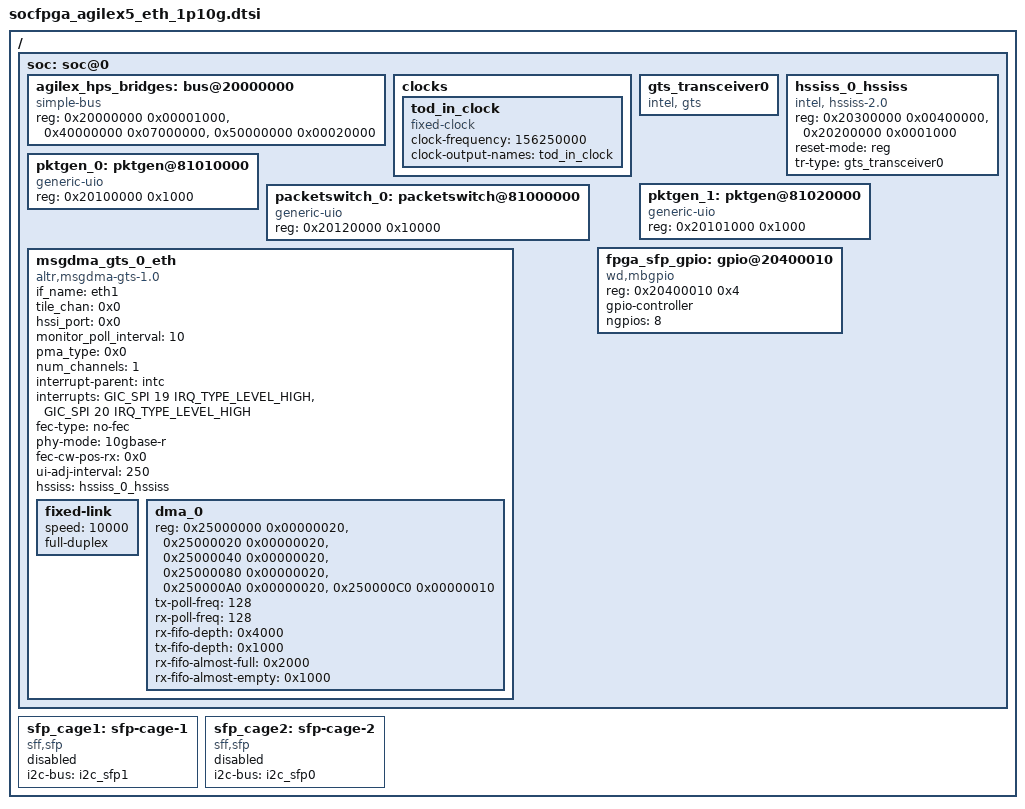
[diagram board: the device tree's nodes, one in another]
// SPDX-License-Identifier: GPL-2.0
/*
 * Copyright(C) 2024 Intel Corporation
 */

//original:
//user_csr 0x0020_0000  0x4020_0000  0x0000_1000
//qhip     0x0030_0000  0x4030_0000  0x0010_0000
//qsfpctrl 0x0404_0000  0x4404_0000  0x0000_4000
//msgdma   0x0500_0000  0x4500_0000  0x0000_0400
//pktcli   0x1000_0000  0x5000_0000  0x0000_1000
//pktsw    0x1001_0000  0x5001_0000  0x0001_0000

//new:
//          Offset       Absolute     Size
// user_csr 0x0020_0000  0x2020_0000  0x0000_1000
// qhip     0x0030_0000  0x2030_0000  0x0010_0000
// qsfpctrl Removed 
// msgdma   0x0500_0000  0x2500_0000  0x0000_0400
// pktcli   0x0010_0000  0x2010_0000  0x0000_1000
// pktsw    0x0012_0000  0x2012_0000  0x0001_0000


// FPGA DDR (2 Gbyte, still working on the other 2 Gbyte ...)
// 0x04_8000_0000 to 0x04_FFFF_FFFF

//The first 32-bit word in each ranges entry represents the child bus flags (or Chip Select / ID), which differentiates between the different physical AXI bridges or address spaces on the Agilex SoC.
//## Breakdown of the Values
//The node specifies #address-cells = <2>;, meaning a child address is made of two 32-bit words.
//
//* 0x00000000 points to the Lightweight HPS-to-FPGA (h2f_lw) bridge.
//* 0x00000001 points to the Main HPS-to-FPGA (h2f) data bridge.
//
//## How the ranges Format Works
//Each mapping inside ranges follows this structure based on your cell counts:
//[child-address-high] [child-address-low] [parent-address] [size]
//Here is how the first two entries map out:
//
//* Lightweight Bridge Mapping:
//
//<0x00000000 0x00000000 0x20000000 0x00001000>
// │          │          │          └─ Size (4KB)
// │          │          └─ Parent Base (0x20000000 in CPU space)
// └─┬────────┘
//   └─ Child Base Address (ID 0, offset 0x0)
//
//* Ethernet Subsystem Mapping:
//
//<0x00000001 0x40000000 0x40000000 0x04000000>
// │          │          │          └─ Size (64MB)
// │          │          └─ Parent Base (0x40000000 in CPU space)
// └─┬────────┘
//   └─ Child Base Address (ID 1, offset 0x40000000)
//
//
//## Why is it structured this way?
//Altera/Intel Agilex SoCs use these ID bits to let the Linux kernel drivers know which physical interconnect/bridge
//path a peripheral belongs to, allowing the system to accurately translate a peripheral's local register space back
//to the main CPU physical memory map.


/{
	soc: soc@0{
//		agilex_hps_bridges: bus@20000000 {
//                compatible = "simple-bus";
//                reg = <0x20000000 0x00001000>,
//                      <0x40000000 0x07000000>,
//		      <0x50000000 0x00020000>;
//                reg-names = "axi_h2f", "axi_h2f_lw";
//                #address-cells = <2>;
//                #size-cells = <1>;
//                ranges =    <0x00000000 0x00000000 0x20000000 0x00001000>, /*axi h2f_lw*/
//                            <0x00000001 0x40000000 0x40000000 0x04000000>, /*axi_h2f: Ethernet subsytem*/
//                            <0x00000001 0x44040000 0x44040000 0x00010000>, /*axi_h2f: QSFP Controller*/
//                            <0x00000001 0x44050000 0x44050000 0x00000040>, /*axi_h2f: Master ToD*/
//                            <0x00000001 0x45000000 0x45000000 0x00300000>, /*axi_h2f: mSGDMA Global CSR, Port CSR*/
//                            <0x00000001 0x50000000 0x50000000 0x00003000>, /*axi_h2f: Port0:HE, Pkt Mux, User CSR*/
//                            <0x00000001 0x50010000 0x50010000 0x00003000>; /*axi_h2f: Port1:HE, Pkt Mux, User CSR*/
//		};

		agilex_hps_bridges: bus@20000000 {
                compatible = "simple-bus";
                reg = <0x20000000 0x00001000>,
                      <0x40000000 0x07000000>,
		      <0x50000000 0x00020000>;
                reg-names = "axi_h2f", "axi_h2f_lw";
                #address-cells = <2>;
                #size-cells = <1>;
                ranges =    <0x00000000 0x00000000 0x20000000 0x00001000>, /*axi h2f_lw*/
				    <0x00000000 0x00200000 0x20200000 0x00001000>, /*axi_h2f_lw: User CSR*/
				    <0x00000000 0x00300000 0x20300000 0x00100000>, /*axi_h2f_lw: QHIP*/
				    <0x00000000 0x05000000 0x25000000 0x00000400>, /*axi_h2f_lw: mSGDMA Global CSR, Port CSR*/
				    <0x00000000 0x00100000 0x20100000 0x00001000>, /*axi_h2f_lw: Pkt CLI*/
				    <0x00000000 0x00120000 0x20120000 0x00010000>; /*axi_h2f_lw: Pkt Switch*/
		};

	
	clocks {
		tod_in_clock: tod_in_clock {
			#clock-cells = <0>;
			compatible = "fixed-clock";
			clock-frequency = <156250000>;
			clock-output-names = "tod_in_clock";
		};
	};

	gts_transceiver0: gts_transceiver0 {
		compatible = "intel, gts";
	};

	hssiss_0_hssiss: hssiss_0_hssiss {
		compatible = "intel, hssiss-2.0";
		reg-names = "sscsr", "usr_csr";
		reg = <0x20300000 0x00400000>,
				<0x20200000 0x0001000>;
				
		reset-mode ="reg";
		tr-type = <&gts_transceiver0>;
	};

		pktgen_0: pktgen@81010000 {
                         compatible = "generic-uio";
						 reg = <0x20100000 0x1000>;
                         reg-names = "pkt_cli";
                };

		pktgen_1: pktgen@81020000 {
					compatible = "generic-uio";
					reg = <0x20101000 0x1000>;
					reg-names = "pkt_cli";
		};

		packetswitch_0: packetswitch@81000000 {
					compatible = "generic-uio";
					reg = <0x20120000 0x10000>;
					reg-names = "packetswitch";
		};

        //sfp_eth0: sfp-eth0 {
        //    compatible = "altera,sfp-mem";
        //    reg-names = "sfp-mem-ctrl";
        //    reg = <0x44040000 0x00001000>;
        //    status = "okay";
        //};

		/*
		 New FPGA : 0x2040014 is RW (but no function). 0x20400010 is now data for input and output:
		 SFP status is located on address 0x20400010. Bit 2,1 and 0 is (sfp1_tx_fault, sfp1_los, sfp1_mod_det)
		 The working SFP is "SFP2" with status bit 6,5 and 4  (sfp2_tx_fault, sfp2_los, sfp2_mod_det).
		 Tx-disable is 0x20400010 bit 3 (SFP1 Tx-dis) and bit 7  (SFP2 Tx-dis).
		 */
		fpga_sfp_gpio: gpio@20400010 {
			compatible = "wd,mbgpio";
			reg = <0x20400010 0x4>;
			gpio-controller;
			#gpio-cells = <2>;
			ngpios = <8>;
		};

		msgdma_gts_0_eth: msgdma_gts_0_eth {
			compatible = "altr,msgdma-gts-1.0";
			#address-cells = <1>;
			#size-cells = <1>;
			ranges;
			if_name = "eth1";
			tile_chan = <0x0>;
			hssi_port = <0x0>;
			monitor_poll_interval = <10>;
			pma_type = <0x0>; // FGT - 0x00, FHT = 0x1000
			num_channels = <1>;
			interrupt-parent = <&intc>;
			interrupt-names = "dma0_tx_irq", "dma0_rx_irq";
			interrupts = <GIC_SPI 19 IRQ_TYPE_LEVEL_HIGH>, <GIC_SPI 20 IRQ_TYPE_LEVEL_HIGH>;
			status = "okay";
			fec-type="no-fec";
			phy-mode = "10gbase-r";
			fec-cw-pos-rx = <0x0>;
			ui-adj-interval = <250>;
			hssiss = <&hssiss_0_hssiss>;
			//sfp = <&sfp_cage2>;
			fixed-link {
				speed = <10000>;
				full-duplex;
			};

		dma_0 {
				reg-names =	"tx_pref"  ,
						"tx_csr"   ,
						"tx_fifo"  ,
						"rx_pref"  ,
						"rx_csr"   ,
						"rx_fifo";
				reg =	<0x25000000 0x00000020>,
					<0x25000020 0x00000020>,
					<0x25000040 0x00000020>,
					<0x25000080 0x00000020>,
					<0x250000A0 0x00000020>,
					<0x250000C0 0x00000010>;
				tx-poll-freq=<128>;
				rx-poll-freq=<128>;
				rx-fifo-depth = <0x4000>;
				tx-fifo-depth = <0x1000>;
				rx-fifo-almost-full = <0x2000>;
				rx-fifo-almost-empty = <0x1000>;
			};
		};
     };

	sfp_cage1: sfp-cage-1 {
		compatible = "sff,sfp";
		/* Point to your respective I2C channel if SFP1 uses a different segment */
		i2c-bus = <&i2c_sfp1>;

		/* Bit 0, 1, 2 for Mod_Det, LOS, Tx_Fault */
		//mod-def0-gpios   = <&fpga_sfp_gpio 0 GPIO_ACTIVE_LOW>;
		//los-gpios        = <&fpga_sfp_gpio 1 GPIO_ACTIVE_HIGH>;
		//tx-fault-gpios   = <&fpga_sfp_gpio 2 GPIO_ACTIVE_HIGH>;

		/* Bit 3 for Tx-Disable */
		//tx-disable-gpios = <&fpga_sfp_gpio 3 GPIO_ACTIVE_HIGH>;

        status = "disabled";
		};

	sfp_cage2: sfp-cage-2 {
		compatible = "sff,sfp";
		i2c-bus = <&i2c_sfp0>; /* Ensure this points to the correct I2C channel for SFP2 */

		/* Bit 4, 5, 6 for Mod_Det, LOS, Tx_Fault */
		//mod-def0-gpios   = <&fpga_sfp_gpio 4 GPIO_ACTIVE_LOW>;
		//los-gpios        = <&fpga_sfp_gpio 5 GPIO_ACTIVE_HIGH>;
		//tx-fault-gpios   = <&fpga_sfp_gpio 6 GPIO_ACTIVE_HIGH>;

		/* Bit 7 for Tx-Disable */
		// tx-disable-gpios = <&fpga_sfp_gpio 7 GPIO_ACTIVE_HIGH>;
		status = "disabled";
	};

};
